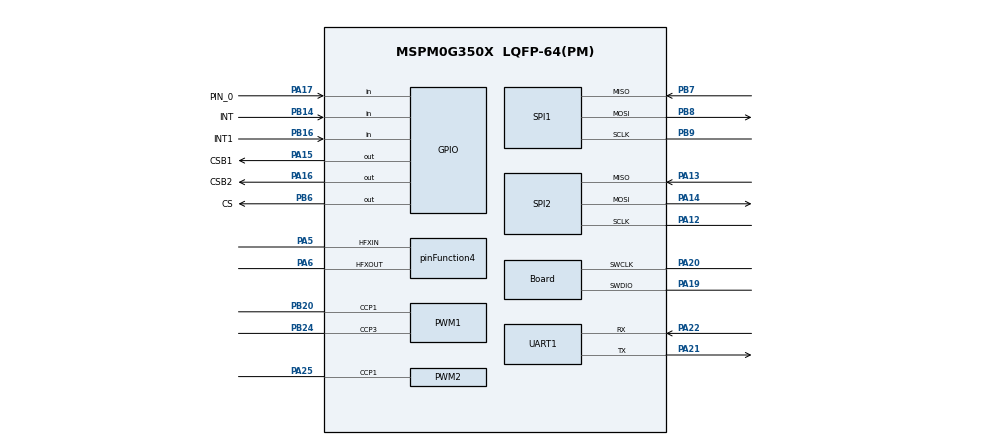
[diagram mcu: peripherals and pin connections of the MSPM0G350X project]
/**
 * @cliArgs --device "MSPM0G350X" --part "Default" --package "LQFP-64(PM)" --product "mspm0_sdk@2.03.00.07"
 * @versions {"tool":"1.23.0+4000"}
 */

/**
 * Import the modules used in this configuration.
 */
const GPIO          = scripting.addModule("/ti/driverlib/GPIO", {}, false);
const GPIO1         = GPIO.addInstance();
const GPIO2         = GPIO.addInstance();
const GPIO3         = GPIO.addInstance();
const PWM           = scripting.addModule("/ti/driverlib/PWM", {}, false);
const PWM1          = PWM.addInstance();
const PWM2          = PWM.addInstance();
const SPI           = scripting.addModule("/ti/driverlib/SPI", {}, false);
const SPI1          = SPI.addInstance();
const SPI2          = SPI.addInstance();
const SYSCTL        = scripting.addModule("/ti/driverlib/SYSCTL");
const SYSTICK       = scripting.addModule("/ti/driverlib/SYSTICK");
const TIMER         = scripting.addModule("/ti/driverlib/TIMER", {}, false);
const TIMER1        = TIMER.addInstance();
const TIMER2        = TIMER.addInstance();
const TIMER3        = TIMER.addInstance();
const TIMER4        = TIMER.addInstance();
const UART          = scripting.addModule("/ti/driverlib/UART", {}, false);
const UART1         = UART.addInstance();
const ProjectConfig = scripting.addModule("/ti/project_config/ProjectConfig");

/**
 * Write custom configuration values to the imported modules.
 */
const divider2       = system.clockTree["HFCLK4MFPCLKDIV"];
divider2.divideValue = 10;

const divider6       = system.clockTree["PLL_CLK2X_DIV"];
divider6.divideValue = 4;

const divider9       = system.clockTree["UDIV"];
divider9.divideValue = 2;

const gate7  = system.clockTree["MFCLKGATE"];
gate7.enable = true;

const gate8  = system.clockTree["MFPCLKGATE"];
gate8.enable = true;

const multiplier2         = system.clockTree["PLL_QDIV"];
multiplier2.multiplyValue = 4;

const mux2       = system.clockTree["CANCLKMUX"];
mux2.inputSelect = "CANCLKMUX_PLLCLK1_OUT";

const mux4       = system.clockTree["EXHFMUX"];
mux4.inputSelect = "EXHFMUX_XTAL";

const mux8       = system.clockTree["HSCLKMUX"];
mux8.inputSelect = "HSCLKMUX_SYSPLL0";

const mux9       = system.clockTree["LFXTMUX"];
mux9.inputSelect = "LFXTMUX_TRUE";

const mux10       = system.clockTree["MFPCLKMUX"];
mux10.inputSelect = "MFPCLKMUX_HFCLK";

const mux12       = system.clockTree["SYSPLLMUX"];
mux12.inputSelect = "zSYSPLLMUX_HFCLK";

const pinFunction4                        = system.clockTree["HFXT"];
pinFunction4.inputFreq                    = 40;
pinFunction4.enable                       = true;
pinFunction4.HFCLKMonitor                 = true;
pinFunction4.HFXTStartup                  = 20;
pinFunction4.peripheral.$assign           = "SYSCTL";
pinFunction4.peripheral.hfxInPin.$assign  = "PA5";
pinFunction4.peripheral.hfxOutPin.$assign = "PA6";

const pinFunction6              = system.clockTree["LFXT"];
pinFunction6.inputFreq          = 32.768;
pinFunction6.LFCLKMonitorEnable = true;

GPIO1.port                           = "PORTA";
GPIO1.$name                          = "BMI088";
GPIO1.associatedPins.create(3);
GPIO1.associatedPins[0].$name        = "CSB1";
GPIO1.associatedPins[0].initialValue = "SET";
GPIO1.associatedPins[0].pin.$assign  = "PA15";
GPIO1.associatedPins[1].$name        = "CSB2";
GPIO1.associatedPins[1].initialValue = "SET";
GPIO1.associatedPins[1].pin.$assign  = "PA16";
GPIO1.associatedPins[2].$name        = "PIN_0";
GPIO1.associatedPins[2].direction    = "INPUT";
GPIO1.associatedPins[2].interruptEn  = true;
GPIO1.associatedPins[2].polarity     = "RISE";
GPIO1.associatedPins[2].pin.$assign  = "PA17";

const Board                       = scripting.addModule("/ti/driverlib/Board", {}, false);
Board.peripheral.$assign          = "DEBUGSS";
Board.peripheral.swclkPin.$assign = "PA20";
Board.peripheral.swdioPin.$assign = "PA19";

GPIO2.$name                          = "BMI270";
GPIO2.port                           = "PORTB";
GPIO2.associatedPins.create(2);
GPIO2.associatedPins[0].$name        = "CS";
GPIO2.associatedPins[0].initialValue = "SET";
GPIO2.associatedPins[0].pin.$assign  = "PB6";
GPIO2.associatedPins[1].$name        = "INT";
GPIO2.associatedPins[1].direction    = "INPUT";
GPIO2.associatedPins[1].interruptEn  = true;
GPIO2.associatedPins[1].polarity     = "RISE";
GPIO2.associatedPins[1].pin.$assign  = "PB14";

GPIO3.$name                         = "BMI088B";
GPIO3.port                          = "PORTB";
GPIO3.associatedPins[0].$name       = "INT1";
GPIO3.associatedPins[0].direction   = "INPUT";
GPIO3.associatedPins[0].interruptEn = true;
GPIO3.associatedPins[0].polarity    = "RISE";
GPIO3.associatedPins[0].pin.$assign = "PB16";

PWM1.clockDivider                       = 8;
PWM1.$name                              = "PWM_Motors";
PWM1.timerCount                         = 1001;
PWM1.ccIndex                            = [1,3];
PWM1.ccp1PinConfig.direction            = scripting.forceWrite("OUTPUT");
PWM1.ccp1PinConfig.hideOutputInversion  = scripting.forceWrite(false);
PWM1.ccp1PinConfig.onlyInternalResistor = scripting.forceWrite(false);
PWM1.ccp1PinConfig.passedPeripheralType = scripting.forceWrite("Digital");
PWM1.ccp1PinConfig.$name                = "ti_driverlib_gpio_GPIOPinGeneric11";
PWM1.peripheral.$assign                 = "TIMA0";
PWM1.peripheral.ccp1Pin.$assign         = "PB20";
PWM1.peripheral.ccp3Pin.$assign         = "PB24";
PWM1.PWM_CHANNEL_3.$name                = "ti_driverlib_pwm_PWMTimerCC3";
PWM1.ccp3PinConfig.$name                = "ti_driverlib_gpio_GPIOPinGeneric13";
PWM1.PWM_CHANNEL_1.$name                = "ti_driverlib_pwm_PWMTimerCC0";

PWM2.$name                              = "PWM_Buzzer";
PWM2.ccIndex                            = [1];
PWM2.clockDivider                       = 8;
PWM2.ccp1PinConfig.direction            = scripting.forceWrite("OUTPUT");
PWM2.ccp1PinConfig.hideOutputInversion  = scripting.forceWrite(false);
PWM2.ccp1PinConfig.onlyInternalResistor = scripting.forceWrite(false);
PWM2.ccp1PinConfig.passedPeripheralType = scripting.forceWrite("Digital");
PWM2.ccp1PinConfig.$name                = "ti_driverlib_gpio_GPIOPinGeneric8";
PWM2.peripheral.$assign                 = "TIMG12";
PWM2.peripheral.ccp1Pin.$assign         = "PA25";
PWM2.PWM_CHANNEL_1.$name                = "ti_driverlib_pwm_PWMTimerCC4";

SPI1.chipSelect                         = [];
SPI1.frameFormat                        = "MOTO3";
SPI1.$name                              = "SPI_Bmi270";
SPI1.targetBitRate                      = 10000000;
SPI1.sclkPinConfig.direction            = scripting.forceWrite("OUTPUT");
SPI1.sclkPinConfig.onlyInternalResistor = scripting.forceWrite(false);
SPI1.sclkPinConfig.passedPeripheralType = scripting.forceWrite("Digital");
SPI1.sclkPinConfig.$name                = "ti_driverlib_gpio_GPIOPinGeneric9";
SPI1.mosiPinConfig.direction            = scripting.forceWrite("OUTPUT");
SPI1.mosiPinConfig.hideOutputInversion  = scripting.forceWrite(false);
SPI1.mosiPinConfig.onlyInternalResistor = scripting.forceWrite(false);
SPI1.mosiPinConfig.passedPeripheralType = scripting.forceWrite("Digital");
SPI1.mosiPinConfig.$name                = "ti_driverlib_gpio_GPIOPinGeneric14";
SPI1.misoPinConfig.onlyInternalResistor = scripting.forceWrite(false);
SPI1.misoPinConfig.passedPeripheralType = scripting.forceWrite("Digital");
SPI1.misoPinConfig.$name                = "ti_driverlib_gpio_GPIOPinGeneric15";
SPI1.peripheral.$assign                 = "SPI1";
SPI1.peripheral.sclkPin.$assign         = "PB9";
SPI1.peripheral.mosiPin.$assign         = "PB8";
SPI1.peripheral.misoPin.$assign         = "PB7";

SPI2.$name                              = "SPI_BMI088";
SPI2.frameFormat                        = "MOTO3";
SPI2.targetBitRate                      = 10000000;
SPI2.sclkPinConfig.direction            = scripting.forceWrite("OUTPUT");
SPI2.sclkPinConfig.onlyInternalResistor = scripting.forceWrite(false);
SPI2.sclkPinConfig.passedPeripheralType = scripting.forceWrite("Digital");
SPI2.sclkPinConfig.$name                = "ti_driverlib_gpio_GPIOPinGeneric0";
SPI2.mosiPinConfig.direction            = scripting.forceWrite("OUTPUT");
SPI2.mosiPinConfig.hideOutputInversion  = scripting.forceWrite(false);
SPI2.mosiPinConfig.onlyInternalResistor = scripting.forceWrite(false);
SPI2.mosiPinConfig.passedPeripheralType = scripting.forceWrite("Digital");
SPI2.mosiPinConfig.$name                = "ti_driverlib_gpio_GPIOPinGeneric1";
SPI2.misoPinConfig.onlyInternalResistor = scripting.forceWrite(false);
SPI2.misoPinConfig.passedPeripheralType = scripting.forceWrite("Digital");
SPI2.misoPinConfig.$name                = "ti_driverlib_gpio_GPIOPinGeneric2";
SPI2.peripheral.$assign                 = "SPI0";
SPI2.peripheral.sclkPin.$assign         = "PA12";
SPI2.peripheral.mosiPin.$assign         = "PA14";
SPI2.peripheral.misoPin.$assign         = "PA13";

SYSCTL.validateClkStatus     = true;
SYSCTL.HFCLKSource           = "HFXT";
SYSCTL.waitState             = "1";
SYSCTL.enableSYSOSCFCL       = true;
SYSCTL.enableROSC            = true;
SYSCTL.forceDefaultClkConfig = true;
SYSCTL.clockTreeEn           = true;

SYSTICK.periodEnable      = true;
SYSTICK.period            = 80000;
SYSTICK.interruptEnable   = true;
SYSTICK.systickEnable     = true;
SYSTICK.interruptPriority = "0";

TIMER1.timerClkDiv        = 8;
TIMER1.timerClkPrescale   = 100;
TIMER1.timerMode          = "PERIODIC";
TIMER1.interrupts         = ["ZERO"];
TIMER1.timerPeriod        = "100 ms";
TIMER1.$name              = "TIMERA1_10hz";
TIMER1.peripheral.$assign = "TIMA1";

TIMER2.timerClkDiv        = 8;
TIMER2.timerClkPrescale   = 100;
TIMER2.timerMode          = "PERIODIC";
TIMER2.timerPeriod        = "5 ms";
TIMER2.interrupts         = ["ZERO"];
TIMER2.$name              = "TIMERG7_200hz";
TIMER2.peripheral.$assign = "TIMG7";

TIMER3.$name              = "TIMERG8_100hz";
TIMER3.timerClkDiv        = 8;
TIMER3.timerClkPrescale   = 100;
TIMER3.timerMode          = "PERIODIC";
TIMER3.timerPeriod        = "10 ms";
TIMER3.interrupts         = ["ZERO"];
TIMER3.peripheral.$assign = "TIMG8";

TIMER4.timerClkDiv        = 8;
TIMER4.timerMode          = "PERIODIC";
TIMER4.interrupts         = ["ZERO"];
TIMER4.timerPeriod        = "1 ms";
TIMER4.$name              = "TIMERG6_1000hz";
TIMER4.peripheral.$assign = "TIMG6";

UART1.$name                            = "UART_OUT";
UART1.uartClkSrc                       = "BUSCLK";
UART1.targetBaudRate                   = 921600;
UART1.enabledInterrupts                = ["RX"];
UART1.peripheral.$assign               = "UART2";
UART1.peripheral.rxPin.$assign         = "PA22";
UART1.peripheral.txPin.$assign         = "PA21";
UART1.txPinConfig.$name                = "ti_driverlib_gpio_GPIOPinGeneric3";
UART1.txPinConfig.direction            = scripting.forceWrite("OUTPUT");
UART1.txPinConfig.hideOutputInversion  = scripting.forceWrite(false);
UART1.txPinConfig.onlyInternalResistor = scripting.forceWrite(false);
UART1.txPinConfig.passedPeripheralType = scripting.forceWrite("Digital");
UART1.rxPinConfig.$name                = "ti_driverlib_gpio_GPIOPinGeneric4";
UART1.rxPinConfig.hideOutputInversion  = scripting.forceWrite(false);
UART1.rxPinConfig.onlyInternalResistor = scripting.forceWrite(false);
UART1.rxPinConfig.passedPeripheralType = scripting.forceWrite("Digital");

ProjectConfig.deviceSpin  = "MSPM0G3507";
ProjectConfig.genLibCMSIS = true;
